VERSION ""

NS_ :

BS_:

BU_: XXX

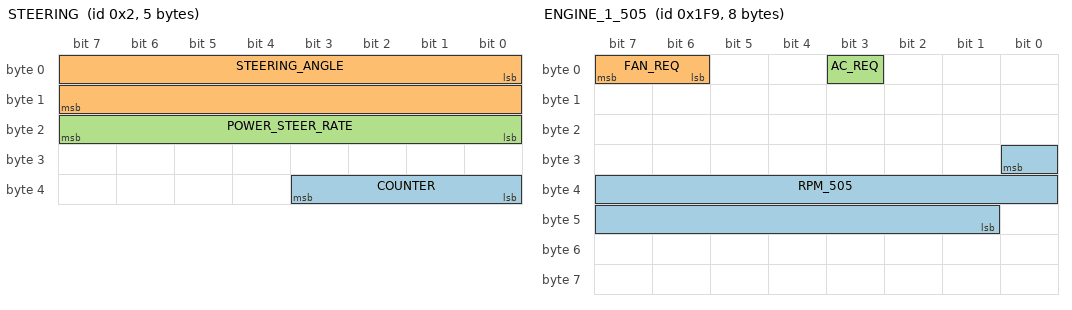
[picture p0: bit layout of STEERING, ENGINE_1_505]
BO_ 2 STEERING: 5 XXX
 SG_ COUNTER : 35|4@0+ (1,0) [0|255] "" XXX
 SG_ STEERING_ANGLE : 0|16@1+ (0.1,0) [0|65535] "deg" XXX
 SG_ POWER_STEER_RATE : 23|8@0+ (1,0) [0|255] "" XXX

BO_ 505 ENGINE_1_505: 8 XXX
 SG_ RPM_505 : 24|16@0+ (0.125,0) [0|45000] "R/min" XXX
 SG_ FAN_REQ : 6|2@1+ (1,0) [0|3] "" XXX
 SG_ AC_REQ : 3|1@1+ (1,0) [0|1] "" XXX

BO_ 561 ENGINE_2_561: 8 XXX
 SG_ Pedal_position_561 : 16|8@1+ (0.5,0) [0|200] "%" XXX

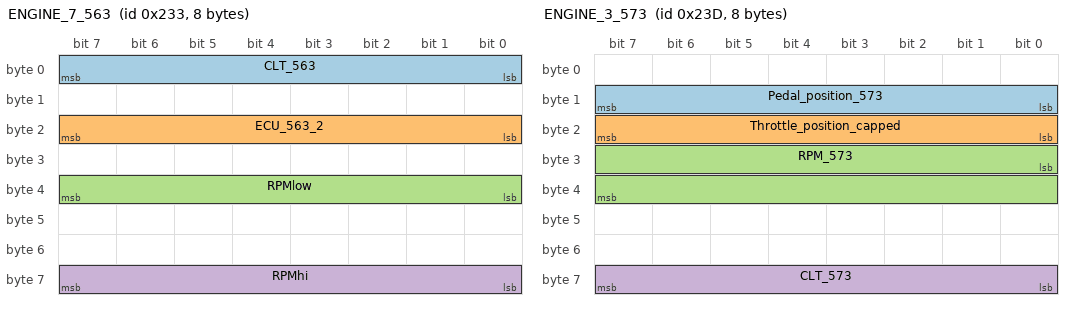
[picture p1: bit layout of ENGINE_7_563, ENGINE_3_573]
BO_ 563 ENGINE_7_563: 8 XXX
 SG_ CLT_563 : 0|8@1+ (0.366666,0) [0|255] "C" XXX
 SG_ ECU_563_2 : 16|8@1+ (1,0) [0|200] "%" XXX
 SG_ RPMlow : 32|8@1+ (3.15,0) [0|45000] "R/min" XXX
 SG_ RPMhi : 56|8@1+ (3.15,0) [0|45000] "R/min" XXX

BO_ 573 ENGINE_3_573: 8 XXX
 SG_ Pedal_position_573 : 8|8@1+ (0.392,0) [0|255] "%" XXX
 SG_ Throttle_position_capped : 16|8@1+ (0.392,0) [0|255] "%" XXX
 SG_ RPM_573 : 24|16@1+ (3.15,0) [0|45000] "R/min" XXX
 SG_ CLT_573 : 56|8@1+ (0.366666,0) [0|255] "C" XXX

BO_ 574 ENGINE_4_574: 8 XXX
 SG_ ECU_23e_0 : 0|8@1+ (1,0) [0|255] "%" XXX
 SG_ Throttle_position_inverted : 16|8@1+ (0.392,0) [0|255] "%" XXX
 SG_ ECU_574_3 : 24|8@1+ (1,0) [0|200] "%" XXX
 SG_ ECU_574_4 : 32|8@1+ (1,0) [0|200] "%" XXX
 SG_ EstimatedTorque : 24|16@1+ (0.1,0) [0|45000] "nM" XXX
 SG_ Throttle_position : 48|8@1+ (0.392,0) [0|255] "%" XXX

BO_ 593 TCU_251_593: 8 XXX
 SG_ tcu_251_0_3 : 0|3@1+ (1,0) [0|255] "%" XXX
 SG_ tcu_251_0 : 0|8@1+ (1,0) [0|255] "%" XXX
 SG_ tcu_251_1 : 8|8@1+ (1,0) [0|255] "%" XXX
 SG_ tcu_251_2 : 16|8@1+ (1,0) [0|255] "%" XXX
 SG_ TCU_251_PRND321 : 24|8@1+ (1,0) [0|255] "%" XXX
 SG_ TCU_IS_P : 24|1@1+ (1,0) [0|255] "%" XXX
 SG_ TCU_IS_R : 25|1@1+ (1,0) [0|255] "%" XXX
 SG_ TCU_IS_N : 26|1@1+ (1,0) [0|255] "%" XXX
 SG_ TCU_IS_D : 27|1@1+ (1,0) [0|255] "%" XXX
 SG_ TCU_IS_4 : 28|1@1+ (1,0) [0|255] "%" XXX
 SG_ TCU_IS_3 : 29|1@1+ (1,0) [0|255] "%" XXX
 SG_ TCU_IS_2 : 30|1@1+ (1,0) [0|255] "%" XXX
 SG_ TCU_IS_1 : 31|1@1+ (1,0) [0|255] "%" XXX
 SG_ tcu_251_4 : 32|8@1+ (1,0) [0|255] "%" XXX
 SG_ tcu_251_5 : 40|8@1+ (1,0) [0|255] "%" XXX
 SG_ tcu_251_5_0_6 : 40|6@1+ (1,0) [0|255] "%" XXX
 SG_ tcu_251_5_6_2 : 46|2@1+ (1,0) [0|255] "%" XXX
 SG_ tcu_251_6 : 48|8@1+ (1,0) [0|255] "%" XXX
 SG_ tcu_251_7 : 56|8@1+ (1,0) [0|255] "%" XXX

BO_ 595 TCU_253_595: 8 XXX
 SG_ tcu_253_0 : 0|8@1+ (1,0) [0|255] "%" XXX
 SG_ tcu_253_2bit_counter : 0|2@1+ (1,0) [0|255] "%" XXX
 SG_ tcu_253_0_2_3 : 2|3@1+ (1,0) [0|255] "%" XXX
 SG_ tcu_253_0_3_3 : 3|3@1+ (1,0) [0|255] "%" XXX
 SG_ TCU_TEMPERATURE : 8|8@1+ (1,0) [0|255] "%" XXX
 SG_ tcu_253_2 : 16|8@1+ (1,0) [0|255] "%" XXX
 SG_ tcu_TORQUE_REDUCTION_AMOUNT : 24|8@1+ (1,0) [0|255] "%" XXX
 SG_ TCU_OUTPUT_SHAFT : 32|16@1+ (1,0) [0|45000] "r/min" XXX
 SG_ TCU_INPUT_SHAFT : 48|16@1+ (1,0) [0|45000] "r/min" XXX

BO_ 640 SPEED: 8 XXX
 SG_ SPEED : 32|16@1+ (0.01,0) [0|45000] "km/h" XXX

BO_ 644 ABS_1: 8 XXX
 SG_ WHEEL_1 : 8|16@0+ (0.01,0) [0|45000] "km/h" XXX
 SG_ WHEEL_2 : 24|16@0+ (0.01,0) [0|45000] "km/h" XXX

BO_ 645 ABS_2: 8 XXX
 SG_ WHEEL_3 : 8|16@0+ (0.01,0) [0|45000] "km/h" XXX
 SG_ WHEEL_4 : 24|16@0+ (0.01,0) [0|45000] "km/h" XXX

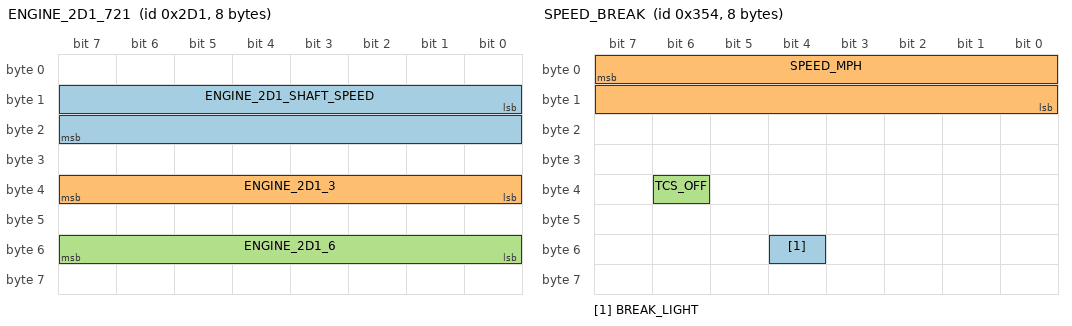
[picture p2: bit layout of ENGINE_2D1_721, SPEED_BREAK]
BO_ 721 ENGINE_2D1_721: 8 XXX
 SG_ ENGINE_2D1_SHAFT_SPEED : 8|16@1+ (1,0) [0|45000] "x" XXX

 SG_ ENGINE_2D1_3 : 32|8@1+ (1,0) [0|45000] "x" XXX
 SG_ ENGINE_2D1_6 : 48|8@1+ (1,0) [0|45000] "x" XXX

BO_ 852 SPEED_BREAK: 8 XXX
 SG_ BREAK_LIGHT : 52|1@0+ (1,0) [0|3] "" XXX
 SG_ SPEED_MPH : 7|16@0+ (0.0066,0) [0|65535] "mph" XXX
 SG_ TCS_OFF : 38|1@0+ (1,0) [0|255] "" XXX

BO_ 861 BCM: 8 XXX

BO_ 1361 ENGINE_5: 8 XXX
 SG_ CLT : 0|8@1+ (1,-45) [-45|150] "" XXX

BO_ 1408 ENGINE_6: 8 XXX
 SG_ RPM_1406_BROKEN : 7|16@0+ (1.5,0) [0|65535] "" XXX
 SG_ OIL_TEMP : 32|8@1+ (1,-40) [-40|150] "" XXX

BO_ 1477 MILEAGE: 8 XXX
